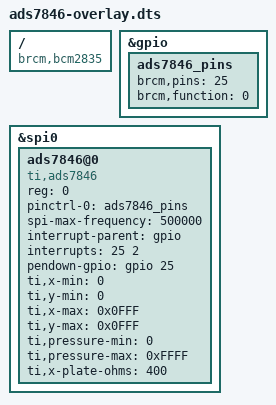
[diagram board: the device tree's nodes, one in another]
/dts-v1/;
/plugin/;

/ {
    compatible = "brcm,bcm2835", "brcm,bcm2837";

    fragment@0 {
        target = <&gpio>;
        __overlay__ {
            ads7846_pins: ads7846_pins {
                brcm,pins = <25>; /* GPIO25 for PENIRQ */
                brcm,function = <0>; /* input */
            };
        };
    };

    fragment@1 {
        target = <&spi0>;
        __overlay__ {
            #address-cells = <1>;
            #size-cells = <0>;
            status = "okay";

            ads7846@0 {
                compatible = "ti,ads7846";
                reg = <0>;
                status = "okay";
                pinctrl-names = "default";
                pinctrl-0 = <&ads7846_pins>;
                spi-max-frequency = <500000>;
                interrupt-parent = <&gpio>;
                interrupts = <25 2>;
                pendown-gpio = <&gpio 25 0>;

                /* Optional properties */
                ti,x-min = /bits/ 16 <0>;
                ti,y-min = /bits/ 16 <0>;
                ti,x-max = /bits/ 16 <0x0FFF>;
                ti,y-max = /bits/ 16 <0x0FFF>;
                ti,pressure-min = /bits/ 16 <0>;
                ti,pressure-max = /bits/ 16 <0xFFFF>;
                ti,x-plate-ohms = /bits/ 16 <400>;
            };
        };
    };
};

